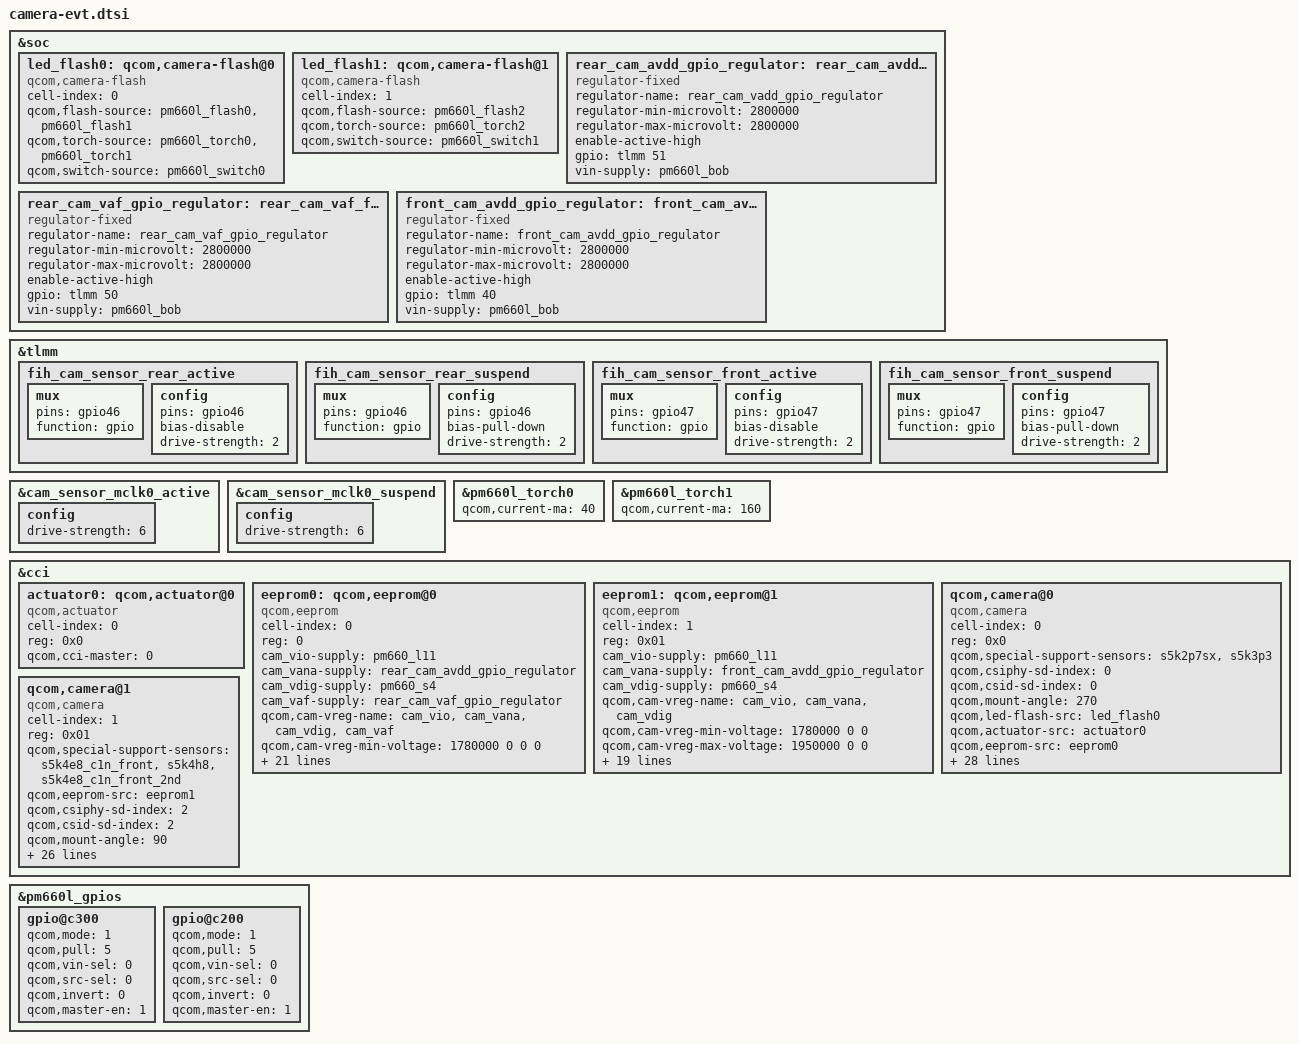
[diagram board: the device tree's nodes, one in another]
/*
 * Copyright (c) 2016, The Linux Foundation. All rights reserved.
 *
 * This program is free software; you can redistribute it and/or modify
 * it under the terms of the GNU General Public License version 2 and
 * only version 2 as published by the Free Software Foundation.
 *
 * This program is distributed in the hope that it will be useful,
 * but WITHOUT ANY WARRANTY; without even the implied warranty of
 * MERCHANTABILITY or FITNESS FOR A PARTICULAR PURPOSE.  See the
 * GNU General Public License for more details.
 */

&soc {
	led_flash0: qcom,camera-flash@0 {
		cell-index = <0>;
		compatible = "qcom,camera-flash";
		qcom,flash-source = <&pm660l_flash0 &pm660l_flash1>;
		qcom,torch-source = <&pm660l_torch0 &pm660l_torch1>;
		qcom,switch-source = <&pm660l_switch0>;
		status = "ok";
	};

	led_flash1: qcom,camera-flash@1 {
		cell-index = <1>;
		compatible = "qcom,camera-flash";
		qcom,flash-source = <&pm660l_flash2>;
		qcom,torch-source = <&pm660l_torch2>;
		qcom,switch-source = <&pm660l_switch1>;
		status = "ok";
	};

	rear_cam_avdd_gpio_regulator: rear_cam_avdd_fixed_regulator {
		compatible = "regulator-fixed";
		regulator-name = "rear_cam_vadd_gpio_regulator";
		regulator-min-microvolt = <2800000>;
		regulator-max-microvolt = <2800000>;
		enable-active-high;
		gpio = <&tlmm 51 0>;
		vin-supply = <&pm660l_bob>;
	};

	rear_cam_vaf_gpio_regulator: rear_cam_vaf_fixed_regulator {
		compatible = "regulator-fixed";
		regulator-name = "rear_cam_vaf_gpio_regulator";
		regulator-min-microvolt = <2800000>;
		regulator-max-microvolt = <2800000>;
		enable-active-high;
		gpio = <&tlmm 50 0>;
		vin-supply = <&pm660l_bob>;
	};

	front_cam_avdd_gpio_regulator: front_cam_avdd_fixed_regulator {
		compatible = "regulator-fixed";
		regulator-name = "front_cam_avdd_gpio_regulator";
		regulator-min-microvolt = <2800000>;
		regulator-max-microvolt = <2800000>;
		enable-active-high;
		gpio = <&tlmm 40 0>;
		vin-supply = <&pm660l_bob>;
	};

};

&tlmm {
		fih_cam_sensor_rear_active: fih_cam_sensor_rear_active {
			/* RESET */
			mux {
				pins = "gpio46";
				function = "gpio";
			};

			config {
				pins = "gpio46";
				bias-disable; /* No PULL */
				drive-strength = <2>; /* 2 MA */
			};
		};

		fih_cam_sensor_rear_suspend: fih_cam_sensor_rear_suspend {
			/* RESET */
			mux {
				pins = "gpio46";
				function = "gpio";
			};

			config {
				pins = "gpio46";
				bias-pull-down; /* PULL DOWN */
				drive-strength = <2>; /* 2 MA */
			};
		};

		fih_cam_sensor_front_active: fih_cam_sensor_front_active {
			/* RESET */
			mux {
				pins = "gpio47";
				function = "gpio";
			};

			config {
				pins = "gpio47";
				bias-disable; /* No PULL */
				drive-strength = <2>; /* 2 MA */
			};
		};

		fih_cam_sensor_front_suspend: fih_cam_sensor_front_suspend {
			/* RESET */
			mux {
				pins = "gpio47";
				function = "gpio";
			};

			config {
				pins = "gpio47";
				bias-pull-down; /* PULL DOWN */
				drive-strength = <2>; /* 2 MA */
			};
		};
};

/*Camera De-sense, raise mclk driving strength from 2MA to 6mA*/
&cam_sensor_mclk0_active {
			config {
				drive-strength = <6>; /* 6 MA */
			};
};
&cam_sensor_mclk0_suspend {
			config {
				drive-strength = <6>; /* 6 MA */
			};
};

/*Modify Torch current*/
/*amber*/
&pm660l_torch0 {
	qcom,current-ma = <40>;
};

/*white*/
&pm660l_torch1 {
	qcom,current-ma = <160>;
};

/* CCI portion*/
&cci {
        /delete-node/qcom,camera@0;
        /delete-node/qcom,camera@1;
        /delete-node/qcom,camera@2;
        /delete-node/qcom,eeprom@0;
        /delete-node/qcom,eeprom@1;
        /delete-node/qcom,actuator@0;
        /delete-node/qcom,actuator@1;
        /delete-node/qcom,ois@0;
};

&cci {
	actuator0: qcom,actuator@0 {
		cell-index = <0>;
		reg = <0x0>;
		compatible = "qcom,actuator";
		qcom,cci-master = <0>;
/*
		gpios = <&tlmm 50 0>;
		qcom,gpio-vaf = <0>;
		qcom,gpio-req-tbl-num = <0>;
		qcom,gpio-req-tbl-flags = <0>;
		qcom,gpio-req-tbl-label = "CAM_VAF";
		pinctrl-names = "cam_default", "cam_suspend";
		pinctrl-0 = <&cam_actuator_vaf_active>;
		pinctrl-1 = <&cam_actuator_vaf_suspend>;
*/
	};

	eeprom0: qcom,eeprom@0 {
		cell-index = <0>;
		reg = <0>;
		compatible = "qcom,eeprom";
		cam_vio-supply = <&pm660_l11>;
		cam_vana-supply = <&rear_cam_avdd_gpio_regulator>;
		cam_vdig-supply = <&pm660_s4>;
		cam_vaf-supply = <&rear_cam_vaf_gpio_regulator>;
		qcom,cam-vreg-name = "cam_vio", "cam_vana", "cam_vdig", "cam_vaf";
		qcom,cam-vreg-min-voltage = <1780000 0 0 0>;
		qcom,cam-vreg-max-voltage = <1950000 0 0 0>;
		qcom,cam-vreg-op-mode = <105000 80000 105000 80000>;
		qcom,gpio-no-mux = <0>;
		pinctrl-names = "cam_default", "cam_suspend";
		pinctrl-0 = <&cam_sensor_mclk0_active
				&fih_cam_sensor_rear_active>;
		pinctrl-1 = <&cam_sensor_mclk0_suspend
				&fih_cam_sensor_rear_suspend>;
		gpios = <&tlmm 32 0>,
			<&tlmm 46 0>,
			<&pm660l_gpios 4 0>;
		qcom,gpio-reset = <1>;
		qcom,gpio-vdig = <2>;
		qcom,gpio-req-tbl-num = <0 1 2>;
		qcom,gpio-req-tbl-flags = <1 0 0>;
		qcom,gpio-req-tbl-label = "CAMIF_MCLK",
					"CAM_RESET",
					"CAM_VDIG";
		qcom,sensor-position = <0>;
		qcom,sensor-mode = <0>;
		qcom,cci-master = <0>;
		status = "ok";
		clocks = <&clock_mmss MCLK0_CLK_SRC>,
				<&clock_mmss MMSS_CAMSS_MCLK0_CLK>;
		clock-names = "cam_src_clk", "cam_clk";
		qcom,clock-rates = <24000000 0>;
	};

	eeprom1: qcom,eeprom@1 {
		cell-index = <1>;
		reg = <0x01>;
		compatible = "qcom,eeprom";
		cam_vio-supply = <&pm660_l11>;
		cam_vana-supply = <&front_cam_avdd_gpio_regulator>;
		cam_vdig-supply = <&pm660_s4>;
		qcom,cam-vreg-name = "cam_vio", "cam_vana", "cam_vdig";
		qcom,cam-vreg-min-voltage = <1780000 0 0>;
		qcom,cam-vreg-max-voltage = <1950000 0 0>;
		qcom,cam-vreg-op-mode = <105000 80000 105000>;
		qcom,gpio-no-mux = <0>;
		pinctrl-names = "cam_default", "cam_suspend";
		pinctrl-0 = <&cam_sensor_mclk1_active
				&fih_cam_sensor_front_active>;
		pinctrl-1 = <&cam_sensor_mclk1_suspend
				&fih_cam_sensor_front_suspend>;
		gpios = <&tlmm 33 0>,
			<&tlmm 47 0>,
			<&pm660l_gpios 3 0>;
		qcom,gpio-reset = <1>;
		qcom,gpio-vdig = <2>;
		qcom,gpio-req-tbl-num = <0 1 2>;
		qcom,gpio-req-tbl-flags = <1 0 0>;
		qcom,gpio-req-tbl-label = "CAMIF_MCLK2",
					"CAM_RESET2",
					"CAM_VDIG";
		qcom,sensor-position = <1>;
		qcom,sensor-mode = <0>;
		qcom,cci-master = <1>;
		status = "ok";
		clocks = <&clock_mmss MCLK1_CLK_SRC>,
				<&clock_mmss MMSS_CAMSS_MCLK1_CLK>;
		clock-names = "cam_src_clk", "cam_clk";
		qcom,clock-rates = <23076923 0>;
	};

	qcom,camera@0 {
		cell-index = <0>;
		compatible = "qcom,camera";
		reg = <0x0>;
		qcom,special-support-sensors = "s5k2p7sx","s5k3p3";
		qcom,csiphy-sd-index = <0>;
		qcom,csid-sd-index = <0>;
		qcom,mount-angle = <270>;
		qcom,led-flash-src = <&led_flash0>;
		qcom,actuator-src = <&actuator0>;
		qcom,eeprom-src = <&eeprom0>;
		cam_vio-supply = <&pm660_l11>;
		cam_vana-supply = <&rear_cam_avdd_gpio_regulator>;
		cam_vdig-supply = <&pm660_s4>;
		cam_vaf-supply = <&rear_cam_vaf_gpio_regulator>;
		qcom,cam-vreg-name = "cam_vio", "cam_vana", "cam_vdig", "cam_vaf";
		qcom,cam-vreg-min-voltage = <1780000 0 0 0>;
		qcom,cam-vreg-max-voltage = <1950000 0 0 0>;
		qcom,cam-vreg-op-mode = <105000 80000 105000 80000>;
		qcom,gpio-no-mux = <0>;
		pinctrl-names = "cam_default", "cam_suspend";
		pinctrl-0 = <&cam_sensor_mclk0_active
				 &fih_cam_sensor_rear_active>;
		pinctrl-1 = <&cam_sensor_mclk0_suspend
				 &fih_cam_sensor_rear_suspend>;
		gpios = <&tlmm 32 0>,
			<&tlmm 46 0>,
			<&pm660l_gpios 4 0>;
		qcom,gpio-reset = <1>;
		qcom,gpio-vdig = <2>;
		qcom,gpio-req-tbl-num = <0 1 2>;
		qcom,gpio-req-tbl-flags = <1 0 0>;
		qcom,gpio-req-tbl-label = "CAMIF_MCLK",
					"CAM_RESET",
					"CAM_VDIG";
		qcom,sensor-position = <0>;
		qcom,sensor-mode = <0>;
		qcom,cci-master = <0>;
		status = "ok";
		clocks = <&clock_mmss MCLK0_CLK_SRC>,
			<&clock_mmss MMSS_CAMSS_MCLK0_CLK>;
		clock-names = "cam_src_clk", "cam_clk";
		qcom,clock-rates = <24000000 0>;
	};

	qcom,camera@1 {
		cell-index = <1>;
		compatible = "qcom,camera";
		reg = <0x01>;
		qcom,special-support-sensors = "s5k4e8_c1n_front","s5k4h8","s5k4e8_c1n_front_2nd";
		qcom,eeprom-src = <&eeprom1>;
		qcom,csiphy-sd-index = <2>;
		qcom,csid-sd-index = <2>;
		qcom,mount-angle = <90>;
		cam_vio-supply = <&pm660_l11>;
		cam_vana-supply = <&front_cam_avdd_gpio_regulator>;
		cam_vdig-supply = <&pm660_s4>;
		qcom,cam-vreg-name = "cam_vio", "cam_vana", "cam_vdig";
		qcom,cam-vreg-min-voltage = <1780000 0 0>;
		qcom,cam-vreg-max-voltage = <1950000 0 0>;
		qcom,cam-vreg-op-mode = <105000 80000 105000>;
		qcom,gpio-no-mux = <0>;
		pinctrl-names = "cam_default", "cam_suspend";
		pinctrl-0 = <&cam_sensor_mclk1_active
				 &fih_cam_sensor_front_active>;
		pinctrl-1 = <&cam_sensor_mclk1_suspend
				 &fih_cam_sensor_front_suspend>;
		gpios = <&tlmm 33 0>,
			<&tlmm 47 0>,
			<&pm660l_gpios 3 0>;
		qcom,gpio-reset = <1>;
		qcom,gpio-vdig = <2>;
		qcom,gpio-req-tbl-num = <0 1 2>;
		qcom,gpio-req-tbl-flags = <1 0 0>;
		qcom,gpio-req-tbl-label = "CAMIF_MCLK2",
					"CAM_RESET2",
					"CAM_VDIG";
		qcom,sensor-position = <1>;
		qcom,sensor-mode = <0>;
		qcom,cci-master = <1>;
		status = "ok";
		clocks = <&clock_mmss MCLK1_CLK_SRC>,
			<&clock_mmss MMSS_CAMSS_MCLK1_CLK>;
		clock-names = "cam_src_clk", "cam_clk";
		qcom,clock-rates = <23076923 0>;
	};
};

&pm660l_gpios {
	gpio@c300 { /* GPIO4 -CAMERA SENSOR 0 VDIG*/
		qcom,mode = <1>;                /* Output */
		qcom,pull = <5>;                /* No Pull */
		qcom,vin-sel = <0>;             /* VIN1 GPIO_LV */
		qcom,src-sel = <0>;             /* GPIO */
		qcom,invert = <0>;              /* Invert */
		qcom,master-en = <1>;           /* Enable GPIO */
		status = "ok";
	};

	gpio@c200 { /* GPIO3 -CAMERA SENSOR 2 VDIG*/
		qcom,mode = <1>;                /* Output */
		qcom,pull = <5>;                /* No Pull */
		qcom,vin-sel = <0>;             /* VIN1 GPIO_LV */
		qcom,src-sel = <0>;             /* GPIO */
		qcom,invert = <0>;              /* Invert */
		qcom,master-en = <1>;           /* Enable GPIO */
		status = "ok";
	};
};
